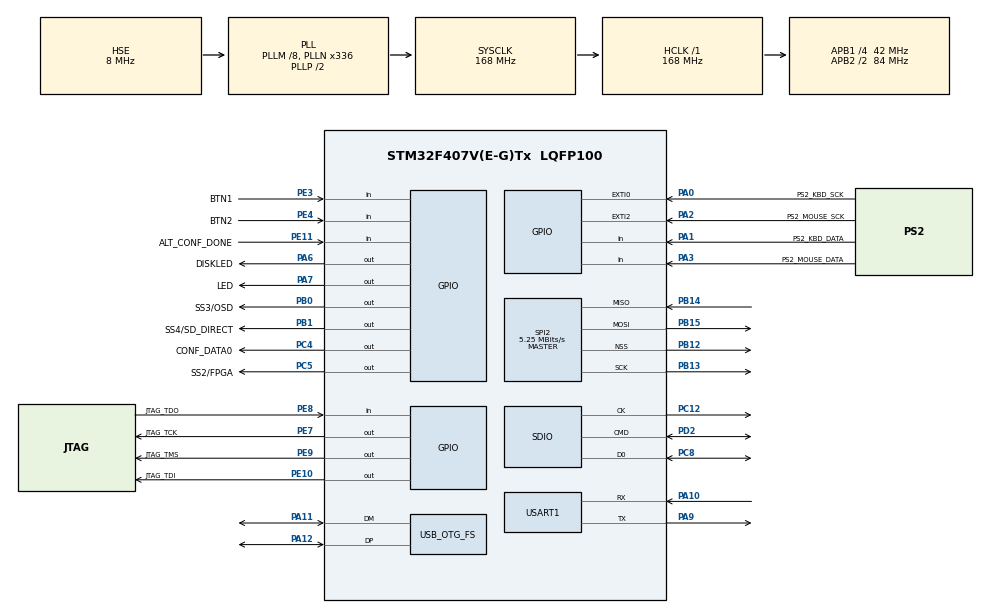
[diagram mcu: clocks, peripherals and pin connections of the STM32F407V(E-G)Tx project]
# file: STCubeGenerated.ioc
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Mcu.Family=STM32F4
Mcu.Name=STM32F407V(E-G)Tx
Mcu.Package=LQFP100
NVIC.EXTI0_IRQn=true\:6\:0\:true\:false\:true
NVIC.EXTI2_IRQn=true\:5\:0\:true\:false\:true
NVIC.OTG_FS_IRQn=true\:1\:0\:true\:false\:true
NVIC.PriorityGroup=NVIC_PRIORITYGROUP_4
NVIC.USART1_IRQn=true\:2\:0\:true\:false\:true
PA0-WKUP.GPIO_Label=PS2_KBD_SCK
PA0-WKUP.GPIO_ModeDefaultEXTI=GPIO_MODE_IT_FALLING
PA0-WKUP.GPIO_PuPd=GPIO_PULLUP
PA0-WKUP.Signal=GPXTI0
PA1.GPIO_Label=PS2_KBD_DATA
PA1.GPIO_PuPd=GPIO_PULLUP
PA1.Signal=GPIO_Input
PA10.Mode=Asynchronous
PA10.Signal=USART1_RX
PA11.Mode=Device_Only
PA11.Signal=USB_OTG_FS_DM
PA12.Mode=Device_Only
PA12.Signal=USB_OTG_FS_DP
PA2.GPIO_Label=PS2_MOUSE_SCK
PA2.GPIO_ModeDefaultEXTI=GPIO_MODE_IT_FALLING
PA2.GPIO_PuPd=GPIO_PULLUP
PA2.Signal=GPXTI2
PA3.GPIO_Label=PS2_MOUSE_DATA
PA3.GPIO_PuPd=GPIO_PULLUP
PA3.Signal=GPIO_Input
PA6.GPIO_Label=DISKLED
PA6.Signal=GPIO_Output
PA7.GPIO_Label=LED
PA7.Signal=GPIO_Output
PA9.Mode=Asynchronous
PA9.Signal=USART1_TX
PB0.GPIO_Label=SS3/OSD
PB0.Signal=GPIO_Output
PB1.GPIO_Label=SS4/SD_DIRECT
PB1.Signal=GPIO_Output
PB12.Mode=NSS_Signal_Hard_Output
PB12.Signal=SPI2_NSS
PB13.Mode=Full_Duplex_Master
PB13.Signal=SPI2_SCK
PB14.Mode=Full_Duplex_Master
PB14.Signal=SPI2_MISO
PB15.Mode=Full_Duplex_Master
PB15.Signal=SPI2_MOSI
PC10.Signal=SDIO_D2
PC11.Signal=SDIO_D3
PC12.Mode=SD_1_bit
PC12.Signal=SDIO_CK
PC14-OSC32_IN.Mode=LSE-External-Oscillator
PC14-OSC32_IN.Signal=RCC_OSC32_IN
PC15-OSC32_OUT.Mode=LSE-External-Oscillator
PC15-OSC32_OUT.Signal=RCC_OSC32_OUT
PC4.GPIO_Label=CONF_DATA0
PC4.Signal=GPIO_Output
PC5.GPIO_Label=SS2/FPGA
PC5.Signal=GPIO_Output
PC8.Mode=SD_1_bit
PC8.Signal=SDIO_D0
PC9.Signal=SDIO_D1
PD2.Mode=SD_1_bit
PD2.Signal=SDIO_CMD
PE10.GPIO_Label=JTAG_TDI
PE10.Signal=GPIO_Output
PE11.GPIO_Label=ALT_CONF_DONE
PE11.Signal=GPIO_Input
PE3.GPIO_Label=BTN1
PE3.Signal=GPIO_Input
PE4.GPIO_Label=BTN2
PE4.Signal=GPIO_Input
PE7.GPIO_Label=JTAG_TCK
PE7.Signal=GPIO_Output
PE8.GPIO_Label=JTAG_TDO
PE8.Signal=GPIO_Input
PE9.GPIO_Label=JTAG_TMS
PE9.Signal=GPIO_Output
PH0-OSC_IN.Mode=HSE-External-Oscillator
PH0-OSC_IN.Signal=RCC_OSC_IN
PH1-OSC_OUT.Mode=HSE-External-Oscillator
PH1-OSC_OUT.Signal=RCC_OSC_OUT
ProjectManager.HeapSize=0x500
ProjectManager.StackSize=0x400
ProjectManager.TargetToolchain=MDK-ARM V5
RCC.48MHZClocksFreq_Value=48000000
RCC.AHBFreq_Value=168000000
RCC.APB1CLKDivider=RCC_HCLK_DIV4
RCC.APB1Freq_Value=42000000
RCC.APB1TimFreq_Value=84000000
RCC.APB2CLKDivider=RCC_HCLK_DIV2
RCC.APB2Freq_Value=84000000
RCC.APB2TimFreq_Value=168000000
RCC.CortexFreq_Value=168000000
RCC.HCLKFreq_Value=168000000
RCC.HSE_Timout=100
RCC.HSE_VALUE=8000000
RCC.HSI_VALUE=16000000
RCC.PLLM=8
RCC.PLLN=336
RCC.PLLQ=7
RCC.RCC_RTC_Clock_Source=RCC_RTCCLKSOURCE_LSE
RCC.RCC_RTC_Clock_SourceVirtual=RCC_RTCCLKSOURCE_LSE
RCC.RCC_RTC_Clock_Source_FROM_HSE=RCC_RTCCLKSOURCE_HSE_DIV31
RCC.SYSCLKFreq_VALUE=168000000
RCC.SYSCLKSource=RCC_SYSCLKSOURCE_PLLCLK
RCC.VCOOutputFreq_Value=336000000
SDIO.BusWide=SDIO_BUS_WIDE_1B
SPI2.BaudRatePrescaler=SPI_BAUDRATEPRESCALER_8
SPI2.CLKPhase=SPI_PHASE_2EDGE
SPI2.CLKPolarity=SPI_POLARITY_HIGH
SPI2.CalculateBaudRate=5.25 MBits/s
SPI2.Mode=SPI_MODE_MASTER
SPI2.VirtualNSS=VM_NSSHARD
USB_DEVICE.CLASS_NAME-CDC_FS=CDC
USB_DEVICE.CLASS_NAME_FS=CDC
USB_DEVICE.USBD_HandleTypeDef-CDC_FS=hUsbDeviceFS
USB_DEVICE.VirtualMode-CDC_FS=Cdc
USB_DEVICE.VirtualModeFS=Cdc_FS
USB_OTG_FS.VirtualMode=Device_Only
USB_OTG_FS.vbus_sensing_enable=DISABLE
VP_RTC_VS_RTC_Alarm_A_Intern.Mode=Alarm A
VP_USB_DEVICE_VS_USB_DEVICE_CDC_FS.Mode=CDC_FS
board=STCubeGenerated

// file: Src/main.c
/**
  ******************************************************************************
  * File Name          : main.c
  * Description        : Main program body
  ******************************************************************************
  *
  * COPYRIGHT(c) 2016 STMicroelectronics
  *
  * Redistribution and use in source and binary forms, with or without modification,
  * are permitted provided that the following conditions are met:
  *   1. Redistributions of source code must retain the above copyright notice,
  *      this list of conditions and the following disclaimer.
  *   2. Redistributions in binary form must reproduce the above copyright notice,
  *      this list of conditions and the following disclaimer in the documentation
  *      and/or other materials provided with the distribution.
  *   3. Neither the name of STMicroelectronics nor the names of its contributors
  *      may be used to endorse or promote products derived from this software
  *      without specific prior written permission.
  *
  * THIS SOFTWARE IS PROVIDED BY THE COPYRIGHT HOLDERS AND CONTRIBUTORS "AS IS"
  * AND ANY EXPRESS OR IMPLIED WARRANTIES, INCLUDING, BUT NOT LIMITED TO, THE
  * IMPLIED WARRANTIES OF MERCHANTABILITY AND FITNESS FOR A PARTICULAR PURPOSE ARE
  * DISCLAIMED. IN NO EVENT SHALL THE COPYRIGHT HOLDER OR CONTRIBUTORS BE LIABLE
  * FOR ANY DIRECT, INDIRECT, INCIDENTAL, SPECIAL, EXEMPLARY, OR CONSEQUENTIAL
  * DAMAGES (INCLUDING, BUT NOT LIMITED TO, PROCUREMENT OF SUBSTITUTE GOODS OR
  * SERVICES; LOSS OF USE, DATA, OR PROFITS; OR BUSINESS INTERRUPTION) HOWEVER
  * CAUSED AND ON ANY THEORY OF LIABILITY, WHETHER IN CONTRACT, STRICT LIABILITY,
  * OR TORT (INCLUDING NEGLIGENCE OR OTHERWISE) ARISING IN ANY WAY OUT OF THE USE
  * OF THIS SOFTWARE, EVEN IF ADVISED OF THE POSSIBILITY OF SUCH DAMAGE.
  *
  ******************************************************************************
  */
#include "stm32f4xx_hal.h"
#include "usb_device.h"

RTC_HandleTypeDef hrtc;

SD_HandleTypeDef hsd;
HAL_SD_CardInfoTypedef SDCardInfo;

SPI_HandleTypeDef hspi2;

UART_HandleTypeDef huart1;

/* USER CODE BEGIN PV */
/* Private variables ---------------------------------------------------------*/

/* USER CODE END PV */

void SystemClock_Config(void);
void Error_Handler(void);
static void MX_GPIO_Init(void);
static void MX_SPI2_Init(void);
static void MX_USART1_UART_Init(void);
static void MX_SDIO_SD_Init(void);
static void MX_RTC_Init(void);

/* USER CODE BEGIN PFP */
/* Private function prototypes -----------------------------------------------*/
extern int main_stm32(void);

/* USER CODE END PFP */

int main(void)
{

  /* MCU Configuration----------------------------------------------------------*/

  /* Reset of all peripherals, Initializes the Flash interface and the Systick. */
  HAL_Init();

  /* Configure the system clock */
  SystemClock_Config();

  /* Initialize all configured peripherals */
  MX_GPIO_Init();
  MX_SPI2_Init();
  MX_USART1_UART_Init();
  MX_SDIO_SD_Init();
  MX_USB_DEVICE_Init();
  MX_RTC_Init();

  /* USER CODE BEGIN 2 */
  /* Workaround .after power on SD card initialized improperly */
  MX_SDIO_SD_Init();
  /* USER CODE END 2 */

  /* Infinite loop */
  /* USER CODE BEGIN WHILE */
#if 0
  while (1)
  {
    HAL_GPIO_TogglePin(LED_GPIO_Port, LED_Pin);
    HAL_Delay(1000);
  /* USER CODE END WHILE */

  /* USER CODE BEGIN 3 */

  }
#else
  main_stm32();
#endif
  /* USER CODE END 3 */

}

/** System Clock Configuration
*/
void SystemClock_Config(void)
{

  RCC_OscInitTypeDef RCC_OscInitStruct;
  RCC_ClkInitTypeDef RCC_ClkInitStruct;
  RCC_PeriphCLKInitTypeDef PeriphClkInitStruct;

  __HAL_RCC_PWR_CLK_ENABLE();

  __HAL_PWR_VOLTAGESCALING_CONFIG(PWR_REGULATOR_VOLTAGE_SCALE1);

  RCC_OscInitStruct.OscillatorType = RCC_OSCILLATORTYPE_HSE|RCC_OSCILLATORTYPE_LSE;
  RCC_OscInitStruct.HSEState = RCC_HSE_ON;
  RCC_OscInitStruct.LSEState = RCC_LSE_ON;
  RCC_OscInitStruct.PLL.PLLState = RCC_PLL_ON;
  RCC_OscInitStruct.PLL.PLLSource = RCC_PLLSOURCE_HSE;
  RCC_OscInitStruct.PLL.PLLM = 8;
  RCC_OscInitStruct.PLL.PLLN = 336;
  RCC_OscInitStruct.PLL.PLLP = RCC_PLLP_DIV2;
  RCC_OscInitStruct.PLL.PLLQ = 7;
  if (HAL_RCC_OscConfig(&RCC_OscInitStruct) != HAL_OK)
  {
    Error_Handler();
  }

  RCC_ClkInitStruct.ClockType = RCC_CLOCKTYPE_HCLK|RCC_CLOCKTYPE_SYSCLK
                              |RCC_CLOCKTYPE_PCLK1|RCC_CLOCKTYPE_PCLK2;
  RCC_ClkInitStruct.SYSCLKSource = RCC_SYSCLKSOURCE_PLLCLK;
  RCC_ClkInitStruct.AHBCLKDivider = RCC_SYSCLK_DIV1;
  RCC_ClkInitStruct.APB1CLKDivider = RCC_HCLK_DIV4;
  RCC_ClkInitStruct.APB2CLKDivider = RCC_HCLK_DIV2;
  if (HAL_RCC_ClockConfig(&RCC_ClkInitStruct, FLASH_LATENCY_5) != HAL_OK)
  {
    Error_Handler();
  }

  PeriphClkInitStruct.PeriphClockSelection = RCC_PERIPHCLK_RTC;
  PeriphClkInitStruct.RTCClockSelection = RCC_RTCCLKSOURCE_LSE;
  if (HAL_RCCEx_PeriphCLKConfig(&PeriphClkInitStruct) != HAL_OK)
  {
    Error_Handler();
  }

  HAL_SYSTICK_Config(HAL_RCC_GetHCLKFreq()/1000);

  HAL_SYSTICK_CLKSourceConfig(SYSTICK_CLKSOURCE_HCLK);

  /* SysTick_IRQn interrupt configuration */
  HAL_NVIC_SetPriority(SysTick_IRQn, 0, 0);
}

/* RTC init function */
static void MX_RTC_Init(void)
{

  RTC_TimeTypeDef sTime;
  RTC_DateTypeDef sDate;
  RTC_AlarmTypeDef sAlarm;

    /**Initialize RTC and set the Time and Date
    */
  hrtc.Instance = RTC;
  hrtc.Init.HourFormat = RTC_HOURFORMAT_24;
  hrtc.Init.AsynchPrediv = 127;
  hrtc.Init.SynchPrediv = 255;
  hrtc.Init.OutPut = RTC_OUTPUT_DISABLE;
  hrtc.Init.OutPutPolarity = RTC_OUTPUT_POLARITY_HIGH;
  hrtc.Init.OutPutType = RTC_OUTPUT_TYPE_OPENDRAIN;
  if (HAL_RTC_Init(&hrtc) != HAL_OK)
  {
    Error_Handler();
  }

  sTime.Hours = 0x0;
  sTime.Minutes = 0x0;
  sTime.Seconds = 0x0;
  sTime.DayLightSaving = RTC_DAYLIGHTSAVING_NONE;
  sTime.StoreOperation = RTC_STOREOPERATION_RESET;
  if (HAL_RTC_SetTime(&hrtc, &sTime, RTC_FORMAT_BCD) != HAL_OK)
  {
    Error_Handler();
  }

  sDate.WeekDay = RTC_WEEKDAY_MONDAY;
  sDate.Month = RTC_MONTH_JANUARY;
  sDate.Date = 0x1;
  sDate.Year = 0x0;

  if (HAL_RTC_SetDate(&hrtc, &sDate, RTC_FORMAT_BCD) != HAL_OK)
  {
    Error_Handler();
  }

    /**Enable the Alarm A
    */
  sAlarm.AlarmTime.Hours = 0x0;
  sAlarm.AlarmTime.Minutes = 0x0;
  sAlarm.AlarmTime.Seconds = 0x0;
  sAlarm.AlarmTime.SubSeconds = 0x0;
  sAlarm.AlarmTime.DayLightSaving = RTC_DAYLIGHTSAVING_NONE;
  sAlarm.AlarmTime.StoreOperation = RTC_STOREOPERATION_RESET;
  sAlarm.AlarmMask = RTC_ALARMMASK_NONE;
  sAlarm.AlarmSubSecondMask = RTC_ALARMSUBSECONDMASK_ALL;
  sAlarm.AlarmDateWeekDaySel = RTC_ALARMDATEWEEKDAYSEL_DATE;
  sAlarm.AlarmDateWeekDay = 0x1;
  sAlarm.Alarm = RTC_ALARM_A;
  if (HAL_RTC_SetAlarm(&hrtc, &sAlarm, RTC_FORMAT_BCD) != HAL_OK)
  {
    Error_Handler();
  }

}

/* SDIO init function */
static void MX_SDIO_SD_Init(void)
{

  hsd.Instance = SDIO;
  hsd.Init.ClockEdge = SDIO_CLOCK_EDGE_RISING;
  hsd.Init.ClockBypass = SDIO_CLOCK_BYPASS_DISABLE;
  hsd.Init.ClockPowerSave = SDIO_CLOCK_POWER_SAVE_DISABLE;
  hsd.Init.BusWide = SDIO_BUS_WIDE_1B;
  hsd.Init.HardwareFlowControl = SDIO_HARDWARE_FLOW_CONTROL_DISABLE;
  hsd.Init.ClockDiv = 0;
  if (HAL_SD_Init(&hsd, &SDCardInfo) != SD_OK)
  {
    Error_Handler();
  }

}

/* SPI2 init function */
static void MX_SPI2_Init(void)
{

  hspi2.Instance = SPI2;
  hspi2.Init.Mode = SPI_MODE_MASTER;
  hspi2.Init.Direction = SPI_DIRECTION_2LINES;
  hspi2.Init.DataSize = SPI_DATASIZE_8BIT;
  hspi2.Init.CLKPolarity = SPI_POLARITY_HIGH;
  hspi2.Init.CLKPhase = SPI_PHASE_2EDGE;
  hspi2.Init.NSS = SPI_NSS_HARD_OUTPUT;
  hspi2.Init.BaudRatePrescaler = SPI_BAUDRATEPRESCALER_8;
  hspi2.Init.FirstBit = SPI_FIRSTBIT_MSB;
  hspi2.Init.TIMode = SPI_TIMODE_DISABLE;
  hspi2.Init.CRCCalculation = SPI_CRCCALCULATION_DISABLE;
  hspi2.Init.CRCPolynomial = 10;
  if (HAL_SPI_Init(&hspi2) != HAL_OK)
  {
    Error_Handler();
  }

}

/* USART1 init function */
static void MX_USART1_UART_Init(void)
{

  huart1.Instance = USART1;
  huart1.Init.BaudRate = 115200;
  huart1.Init.WordLength = UART_WORDLENGTH_8B;
  huart1.Init.StopBits = UART_STOPBITS_1;
  huart1.Init.Parity = UART_PARITY_NONE;
  huart1.Init.Mode = UART_MODE_TX_RX;
  huart1.Init.HwFlowCtl = UART_HWCONTROL_NONE;
  huart1.Init.OverSampling = UART_OVERSAMPLING_16;
  if (HAL_UART_Init(&huart1) != HAL_OK)
  {
    Error_Handler();
  }

}

/** Configure pins as
        * Analog
        * Input
        * Output
        * EVENT_OUT
        * EXTI
*/
static void MX_GPIO_Init(void)
{

  GPIO_InitTypeDef GPIO_InitStruct;

  /* GPIO Ports Clock Enable */
  __HAL_RCC_GPIOE_CLK_ENABLE();
  __HAL_RCC_GPIOC_CLK_ENABLE();
  __HAL_RCC_GPIOH_CLK_ENABLE();
  __HAL_RCC_GPIOA_CLK_ENABLE();
  __HAL_RCC_GPIOB_CLK_ENABLE();
  __HAL_RCC_GPIOD_CLK_ENABLE();

  /*Configure GPIO pins : BTN1_Pin BTN2_Pin JTAG_TDO_Pin ALT_CONF_DONE_Pin */
  GPIO_InitStruct.Pin = BTN1_Pin|BTN2_Pin|JTAG_TDO_Pin|ALT_CONF_DONE_Pin;
  GPIO_InitStruct.Mode = GPIO_MODE_INPUT;
  GPIO_InitStruct.Pull = GPIO_NOPULL;
  HAL_GPIO_Init(GPIOE, &GPIO_InitStruct);

  /*Configure GPIO pins : PS2_KBD_SCK_Pin PS2_MOUSE_SCK_Pin */
  GPIO_InitStruct.Pin = PS2_KBD_SCK_Pin|PS2_MOUSE_SCK_Pin;
  GPIO_InitStruct.Mode = GPIO_MODE_IT_FALLING;
  GPIO_InitStruct.Pull = GPIO_PULLUP;
  HAL_GPIO_Init(GPIOA, &GPIO_InitStruct);

  /*Configure GPIO pins : PS2_KBD_DATA_Pin PS2_MOUSE_DATA_Pin */
  GPIO_InitStruct.Pin = PS2_KBD_DATA_Pin|PS2_MOUSE_DATA_Pin;
  GPIO_InitStruct.Mode = GPIO_MODE_INPUT;
  GPIO_InitStruct.Pull = GPIO_PULLUP;
  HAL_GPIO_Init(GPIOA, &GPIO_InitStruct);

  /*Configure GPIO pins : DISKLED_Pin LED_Pin */
  GPIO_InitStruct.Pin = DISKLED_Pin|LED_Pin;
  GPIO_InitStruct.Mode = GPIO_MODE_OUTPUT_PP;
  GPIO_InitStruct.Pull = GPIO_NOPULL;
  GPIO_InitStruct.Speed = GPIO_SPEED_FREQ_LOW;
  HAL_GPIO_Init(GPIOA, &GPIO_InitStruct);

  /*Configure GPIO pins : CONF_DATA0_Pin SS2_FPGA_Pin */
  GPIO_InitStruct.Pin = CONF_DATA0_Pin|SS2_FPGA_Pin;
  GPIO_InitStruct.Mode = GPIO_MODE_OUTPUT_PP;
  GPIO_InitStruct.Pull = GPIO_NOPULL;
  GPIO_InitStruct.Speed = GPIO_SPEED_FREQ_LOW;
  HAL_GPIO_Init(GPIOC, &GPIO_InitStruct);

  /*Configure GPIO pins : SS3_OSD_Pin SS4_SD_DIRECT_Pin */
  GPIO_InitStruct.Pin = SS3_OSD_Pin|SS4_SD_DIRECT_Pin;
  GPIO_InitStruct.Mode = GPIO_MODE_OUTPUT_PP;
  GPIO_InitStruct.Pull = GPIO_NOPULL;
  GPIO_InitStruct.Speed = GPIO_SPEED_FREQ_LOW;
  HAL_GPIO_Init(GPIOB, &GPIO_InitStruct);

  /*Configure GPIO pins : JTAG_TCK_Pin JTAG_TMS_Pin JTAG_TDI_Pin */
  GPIO_InitStruct.Pin = JTAG_TCK_Pin|JTAG_TMS_Pin|JTAG_TDI_Pin;
  GPIO_InitStruct.Mode = GPIO_MODE_OUTPUT_PP;
  GPIO_InitStruct.Pull = GPIO_NOPULL;
  GPIO_InitStruct.Speed = GPIO_SPEED_FREQ_LOW;
  HAL_GPIO_Init(GPIOE, &GPIO_InitStruct);

  /*Configure GPIO pin Output Level */
  HAL_GPIO_WritePin(GPIOA, DISKLED_Pin|LED_Pin, GPIO_PIN_RESET);

  /*Configure GPIO pin Output Level */
  HAL_GPIO_WritePin(GPIOC, CONF_DATA0_Pin|SS2_FPGA_Pin, GPIO_PIN_RESET);

  /*Configure GPIO pin Output Level */
  HAL_GPIO_WritePin(GPIOB, SS3_OSD_Pin|SS4_SD_DIRECT_Pin, GPIO_PIN_RESET);

  /*Configure GPIO pin Output Level */
  HAL_GPIO_WritePin(GPIOE, JTAG_TCK_Pin|JTAG_TMS_Pin|JTAG_TDI_Pin, GPIO_PIN_RESET);

  /* EXTI interrupt init*/
  HAL_NVIC_SetPriority(EXTI0_IRQn, 6, 0);
  HAL_NVIC_EnableIRQ(EXTI0_IRQn);

  HAL_NVIC_SetPriority(EXTI2_IRQn, 5, 0);
  HAL_NVIC_EnableIRQ(EXTI2_IRQn);

}

void Error_Handler(void)
{
  /* USER CODE BEGIN Error_Handler */
  /* User can add his own implementation to report the HAL error return state */
#if !defined MIST_STM32_DBG
  while(1)
  {
    HAL_GPIO_TogglePin(LED_GPIO_Port, LED_Pin);
    HAL_Delay(240);
  }
#else
   printf("Error_Handler!!!!!");
#endif
  /* USER CODE END Error_Handler */
}

/************************ (C) COPYRIGHT STMicroelectronics *****END OF FILE****/
